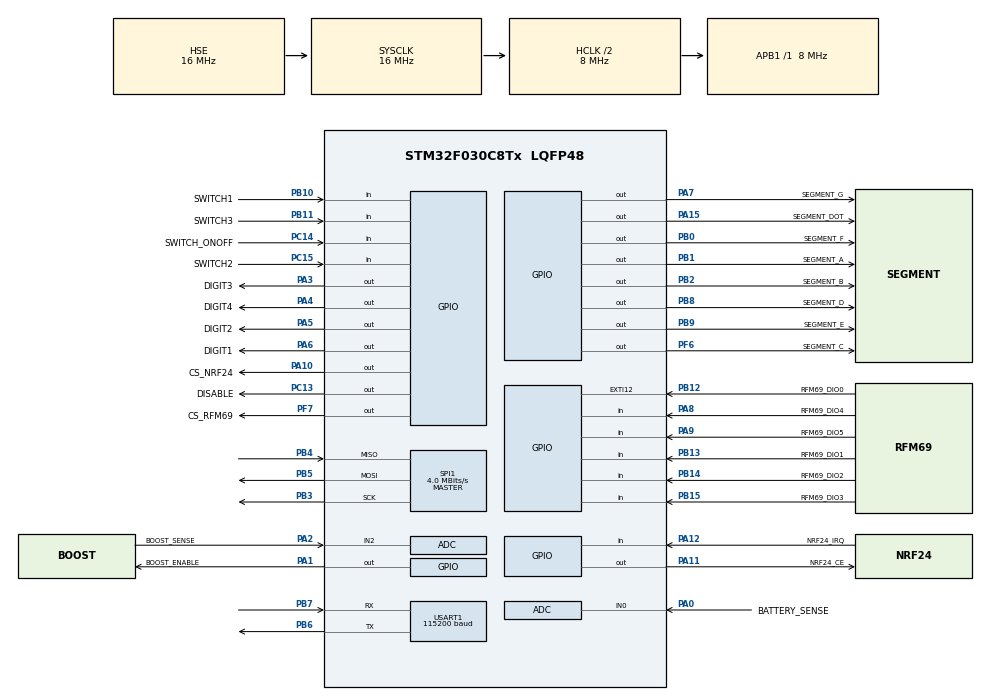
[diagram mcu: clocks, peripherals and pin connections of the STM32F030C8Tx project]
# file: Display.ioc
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ADC.ContinuousConvMode=ENABLE
ADC.DMAContinuousRequests=DISABLE
ADC.SamplingTime=ADC_SAMPLETIME_239CYCLES_5
Dma.ADC.0.Direction=DMA_PERIPH_TO_MEMORY
Dma.ADC.0.Instance=DMA1_Channel1
Dma.ADC.0.MemDataAlignment=DMA_MDATAALIGN_HALFWORD
Dma.ADC.0.MemInc=DMA_MINC_ENABLE
Dma.ADC.0.Mode=DMA_NORMAL
Dma.ADC.0.PeriphDataAlignment=DMA_PDATAALIGN_HALFWORD
Dma.ADC.0.PeriphInc=DMA_PINC_DISABLE
Dma.ADC.0.Priority=DMA_PRIORITY_LOW
Dma.Request0=ADC
Mcu.Family=STM32F0
Mcu.Name=STM32F030C8Tx
Mcu.Package=LQFP48
NVIC.DMA1_Channel1_IRQn=true\:0\:0\:false\:false\:true\:true
NVIC.EXTI4_15_IRQn=true\:0\:0\:false\:false\:true\:true
NVIC.TIM17_IRQn=true\:3\:0\:true\:false\:true\:true
PA0.GPIO_Label=BATTERY_SENSE
PA0.Mode=IN0
PA0.Signal=ADC_IN0
PA1.GPIO_Label=BOOST_ENABLE
PA1.Signal=GPIO_Output
PA10.GPIO_Label=CS_NRF24
PA10.GPIO_Speed=GPIO_SPEED_FREQ_HIGH
PA10.Signal=GPIO_Output
PA11.GPIO_Label=NRF24_CE
PA11.Signal=GPIO_Output
PA12.GPIO_Label=NRF24_IRQ
PA12.GPIO_PuPd=GPIO_PULLDOWN
PA12.Signal=GPIO_Input
PA15.GPIO_Label=SEGMENT_DOT
PA15.GPIO_Speed=GPIO_SPEED_FREQ_HIGH
PA15.Signal=GPIO_Output
PA2.GPIO_Label=BOOST_SENSE
PA2.Mode=IN2
PA2.Signal=ADC_IN2
PA3.GPIO_Label=DIGIT3
PA3.GPIO_Speed=GPIO_SPEED_FREQ_HIGH
PA3.Signal=GPIO_Output
PA4.GPIO_Label=DIGIT4
PA4.GPIO_Speed=GPIO_SPEED_FREQ_HIGH
PA4.Signal=GPIO_Output
PA5.GPIO_Label=DIGIT2
PA5.GPIO_Speed=GPIO_SPEED_FREQ_HIGH
PA5.Signal=GPIO_Output
PA6.GPIO_Label=DIGIT1
PA6.GPIO_Speed=GPIO_SPEED_FREQ_HIGH
PA6.Signal=GPIO_Output
PA7.GPIO_Label=SEGMENT_G
PA7.GPIO_Speed=GPIO_SPEED_FREQ_HIGH
PA7.Signal=GPIO_Output
PA8.GPIO_Label=RFM69_DIO4
PA8.GPIO_PuPd=GPIO_PULLDOWN
PA8.Signal=GPIO_Input
PA9.GPIO_Label=RFM69_DIO5
PA9.GPIO_PuPd=GPIO_PULLDOWN
PA9.Signal=GPIO_Input
PB0.GPIO_Label=SEGMENT_F
PB0.GPIO_Speed=GPIO_SPEED_FREQ_HIGH
PB0.Signal=GPIO_Output
PB1.GPIO_Label=SEGMENT_A
PB1.GPIO_Speed=GPIO_SPEED_FREQ_HIGH
PB1.Signal=GPIO_Output
PB10.GPIO_Label=SWITCH1
PB10.GPIO_PuPd=GPIO_PULLUP
PB10.Signal=GPIO_Input
PB11.GPIO_Label=SWITCH3
PB11.GPIO_PuPd=GPIO_PULLUP
PB11.Signal=GPIO_Input
PB12.GPIO_Label=RFM69_DIO0
PB12.GPIO_PuPd=GPIO_PULLDOWN
PB12.Signal=GPXTI12
PB13.GPIO_Label=RFM69_DIO1
PB13.GPIO_PuPd=GPIO_PULLDOWN
PB13.Signal=GPIO_Input
PB14.GPIO_Label=RFM69_DIO2
PB14.GPIO_PuPd=GPIO_PULLDOWN
PB14.Signal=GPIO_Input
PB15.GPIO_Label=RFM69_DIO3
PB15.GPIO_PuPd=GPIO_PULLDOWN
PB15.Signal=GPIO_Input
PB2.GPIO_Label=SEGMENT_B
PB2.GPIO_Speed=GPIO_SPEED_FREQ_HIGH
PB2.Signal=GPIO_Output
PB3.Mode=Full_Duplex_Master
PB3.Signal=SPI1_SCK
PB4.Mode=Full_Duplex_Master
PB4.Signal=SPI1_MISO
PB5.Mode=Full_Duplex_Master
PB5.Signal=SPI1_MOSI
PB6.Mode=Asynchronous
PB6.Signal=USART1_TX
PB7.Mode=Asynchronous
PB7.Signal=USART1_RX
PB8.GPIO_Label=SEGMENT_D
PB8.GPIO_Speed=GPIO_SPEED_FREQ_HIGH
PB8.Signal=GPIO_Output
PB9.GPIO_Label=SEGMENT_E
PB9.GPIO_Speed=GPIO_SPEED_FREQ_HIGH
PB9.Signal=GPIO_Output
PC13.GPIO_Label=DISABLE
PC13.PinState=GPIO_PIN_SET
PC13.Signal=GPIO_Output
PC14-OSC32_IN.GPIO_Label=SWITCH_ONOFF
PC14-OSC32_IN.GPIO_PuPd=GPIO_PULLUP
PC14-OSC32_IN.Signal=GPIO_Input
PC15-OSC32_OUT.GPIO_Label=SWITCH2
PC15-OSC32_OUT.GPIO_PuPd=GPIO_PULLUP
PC15-OSC32_OUT.Signal=GPIO_Input
PF0-OSC_IN.Mode=HSE-External-Oscillator
PF0-OSC_IN.Signal=RCC_OSC_IN
PF1-OSC_OUT.Mode=HSE-External-Oscillator
PF1-OSC_OUT.Signal=RCC_OSC_OUT
PF6.GPIO_Label=SEGMENT_C
PF6.GPIO_Speed=GPIO_SPEED_FREQ_HIGH
PF6.Signal=GPIO_Output
PF7.GPIO_Label=CS_RFM69
PF7.GPIO_Speed=GPIO_SPEED_FREQ_HIGH
PF7.Signal=GPIO_Output
ProjectManager.HeapSize=0x200
ProjectManager.StackSize=0x400
ProjectManager.TargetToolchain=Makefile
RCC.AHBCLKDivider=RCC_SYSCLK_DIV2
RCC.AHBFreq_Value=8000000
RCC.APB1Freq_Value=8000000
RCC.APB1TimFreq_Value=8000000
RCC.HCLKFreq_Value=8000000
RCC.HSE_VALUE=16000000
RCC.PLLSourceVirtual=RCC_PLLSOURCE_HSE
RCC.SYSCLKFreq_VALUE=16000000
RCC.SYSCLKSource=RCC_SYSCLKSOURCE_HSE
SPI1.CalculateBaudRate=4.0 MBits/s
SPI1.DataSize=SPI_DATASIZE_8BIT
SPI1.Direction=SPI_DIRECTION_2LINES
SPI1.Mode=SPI_MODE_MASTER
SPI1.VirtualType=VM_MASTER
TIM17.Period=1999
TIM17.Prescaler=7
USART1.BaudRate=115200
USART1.VirtualMode-Asynchronous=VM_ASYNC
VP_TIM17_VS_ClockSourceINT.Mode=Enable_Timer
board=Display

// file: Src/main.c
/**
  ******************************************************************************
  * File Name          : main.c
  * Description        : Main program body
  ******************************************************************************
  ** This notice applies to any and all portions of this file
  * that are not between comment pairs USER CODE BEGIN and
  * USER CODE END. Other portions of this file, whether
  * inserted by the user or by software development tools
  * are owned by their respective copyright owners.
  *
  * COPYRIGHT(c) 2017 STMicroelectronics
  *
  * Redistribution and use in source and binary forms, with or without modification,
  * are permitted provided that the following conditions are met:
  *   1. Redistributions of source code must retain the above copyright notice,
  *      this list of conditions and the following disclaimer.
  *   2. Redistributions in binary form must reproduce the above copyright notice,
  *      this list of conditions and the following disclaimer in the documentation
  *      and/or other materials provided with the distribution.
  *   3. Neither the name of STMicroelectronics nor the names of its contributors
  *      may be used to endorse or promote products derived from this software
  *      without specific prior written permission.
  *
  * THIS SOFTWARE IS PROVIDED BY THE COPYRIGHT HOLDERS AND CONTRIBUTORS "AS IS"
  * AND ANY EXPRESS OR IMPLIED WARRANTIES, INCLUDING, BUT NOT LIMITED TO, THE
  * IMPLIED WARRANTIES OF MERCHANTABILITY AND FITNESS FOR A PARTICULAR PURPOSE ARE
  * DISCLAIMED. IN NO EVENT SHALL THE COPYRIGHT HOLDER OR CONTRIBUTORS BE LIABLE
  * FOR ANY DIRECT, INDIRECT, INCIDENTAL, SPECIAL, EXEMPLARY, OR CONSEQUENTIAL
  * DAMAGES (INCLUDING, BUT NOT LIMITED TO, PROCUREMENT OF SUBSTITUTE GOODS OR
  * SERVICES; LOSS OF USE, DATA, OR PROFITS; OR BUSINESS INTERRUPTION) HOWEVER
  * CAUSED AND ON ANY THEORY OF LIABILITY, WHETHER IN CONTRACT, STRICT LIABILITY,
  * OR TORT (INCLUDING NEGLIGENCE OR OTHERWISE) ARISING IN ANY WAY OUT OF THE USE
  * OF THIS SOFTWARE, EVEN IF ADVISED OF THE POSSIBILITY OF SUCH DAMAGE.
  *
  ******************************************************************************
  */
#include "main.h"
#include "stm32f0xx_hal.h"
#include "adc.h"
#include "dma.h"
#include "spi.h"
#include "tim.h"
#include "usart.h"
#include "gpio.h"

/* USER CODE BEGIN Includes */
#include "App.h"
/* USER CODE END Includes */

/* USER CODE BEGIN PV */
/* Private variables ---------------------------------------------------------*/

/* USER CODE END PV */

void SystemClock_Config(void);

/* USER CODE BEGIN PFP */
/* Private function prototypes -----------------------------------------------*/

/* USER CODE END PFP */

int main(void)
{

  /* MCU Configuration----------------------------------------------------------*/

  /* Reset of all peripherals, Initializes the Flash interface and the Systick. */
  HAL_Init();

  /* Configure the system clock */
  SystemClock_Config();

  /* Initialize all configured peripherals */
  MX_GPIO_Init();
  MX_DMA_Init();
  MX_ADC_Init();
  MX_SPI1_Init();
  MX_USART1_UART_Init();
  MX_TIM17_Init();

  /* USER CODE BEGIN 2 */
  App_Start();
  /* USER CODE END 2 */

  /* Infinite loop */
  while (1)
  {

  }

}

/** System Clock Configuration
*/
void SystemClock_Config(void)
{

  RCC_OscInitTypeDef RCC_OscInitStruct;
  RCC_ClkInitTypeDef RCC_ClkInitStruct;
  RCC_PeriphCLKInitTypeDef PeriphClkInit;

    /**Initializes the CPU, AHB and APB busses clocks
    */
  RCC_OscInitStruct.OscillatorType = RCC_OSCILLATORTYPE_HSI14|RCC_OSCILLATORTYPE_HSE;
  RCC_OscInitStruct.HSEState = RCC_HSE_ON;
  RCC_OscInitStruct.HSI14State = RCC_HSI14_ON;
  RCC_OscInitStruct.HSI14CalibrationValue = 16;
  RCC_OscInitStruct.PLL.PLLState = RCC_PLL_NONE;
  if (HAL_RCC_OscConfig(&RCC_OscInitStruct) != HAL_OK)
  {
    _Error_Handler(__FILE__, __LINE__);
  }

    /**Initializes the CPU, AHB and APB busses clocks
    */
  RCC_ClkInitStruct.ClockType = RCC_CLOCKTYPE_HCLK|RCC_CLOCKTYPE_SYSCLK
                              |RCC_CLOCKTYPE_PCLK1;
  RCC_ClkInitStruct.SYSCLKSource = RCC_SYSCLKSOURCE_HSE;
  RCC_ClkInitStruct.AHBCLKDivider = RCC_SYSCLK_DIV2;
  RCC_ClkInitStruct.APB1CLKDivider = RCC_HCLK_DIV1;

  if (HAL_RCC_ClockConfig(&RCC_ClkInitStruct, FLASH_LATENCY_0) != HAL_OK)
  {
    _Error_Handler(__FILE__, __LINE__);
  }

  PeriphClkInit.PeriphClockSelection = RCC_PERIPHCLK_USART1;
  PeriphClkInit.Usart1ClockSelection = RCC_USART1CLKSOURCE_PCLK1;
  if (HAL_RCCEx_PeriphCLKConfig(&PeriphClkInit) != HAL_OK)
  {
    _Error_Handler(__FILE__, __LINE__);
  }

    /**Configure the Systick interrupt time
    */
  HAL_SYSTICK_Config(HAL_RCC_GetHCLKFreq()/1000);

    /**Configure the Systick
    */
  HAL_SYSTICK_CLKSourceConfig(SYSTICK_CLKSOURCE_HCLK);

  /* SysTick_IRQn interrupt configuration */
  HAL_NVIC_SetPriority(SysTick_IRQn, 0, 0);
}

void _Error_Handler(char * file, int line)
{
  while(1)
  {
  }
}

/************************ (C) COPYRIGHT STMicroelectronics *****END OF FILE****/
